# VPAC0_DRU_UTC_VPAC0_DRU_MMR_CFG_DRU_DRU_SET register map
Vendor: Texas Instruments
Peripheral module from a debugger description file (folder J7ES).
Registers are 64-bit, write-only, reset 0x0 unless marked. A register's access mark holds for its fields unless they carry their own. Offsets are as the file gives them; lines under a group give offsets from that group; [hi:lo] are bit positions; {n}, {i} and the like mark numbered series; 'fields as' and 'values as' point back to an identical list; <NAME> marks a mode.

## VPAC0_DRU_UTC_VPAC0_DRU_MMR_CFG_DRU_DRU_SET
0x00 VPAC_UTC0_RT_DRU_SHARED_EVT_SET access per field — DRU Shared Event Set Register
  [0] PROT_ERR wo — Set the Prot Error event
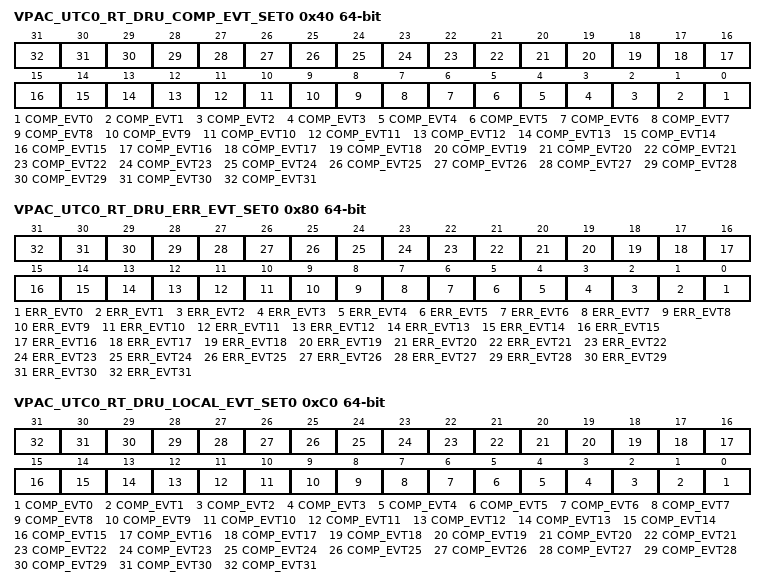
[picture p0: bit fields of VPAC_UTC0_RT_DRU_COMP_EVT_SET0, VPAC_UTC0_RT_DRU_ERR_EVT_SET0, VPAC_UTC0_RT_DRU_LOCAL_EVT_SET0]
0x40 VPAC_UTC0_RT_DRU_COMP_EVT_SET0 — DRU Completion Event Set Register
  [n] COMP_EVT{n} (n=0..31) — Set the Completion Event for channel {n}
0x80 VPAC_UTC0_RT_DRU_ERR_EVT_SET0 — DRU Error Event Set Register
  [n] ERR_EVT{n} (n=0..31) — Set the Error Event for channel {n}
0xC0 VPAC_UTC0_RT_DRU_LOCAL_EVT_SET0 — DRU Local Event Set Register
  [n] COMP_EVT{n} (n=0..31) — Set the Local Event for channel {n}
